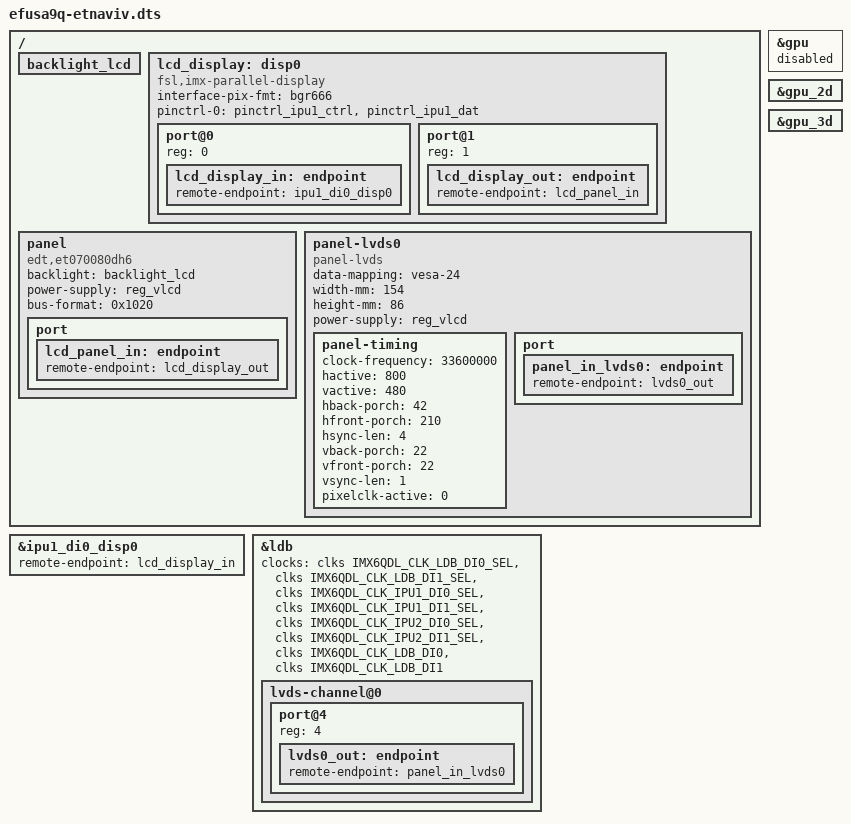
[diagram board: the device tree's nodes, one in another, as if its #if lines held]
#include "efusa9q.dts"

/ {
#ifdef CONFIG_EFUSA9_LCD
	backlight_lcd:backlight_lcd {
	};

	lcd_display: disp0 {
		compatible = "fsl,imx-parallel-display";
		#address-cells = <1>;
		#size-cells = <0>;
		interface-pix-fmt = "bgr666";

		pinctrl-names = "default";
		pinctrl-0 = <&pinctrl_ipu1_ctrl &pinctrl_ipu1_dat>;
		status = "okay";

		port@0 {
			reg = <0>;

			lcd_display_in: endpoint {
				remote-endpoint = <&ipu1_di0_disp0>;
			};
		};

		port@1 {
			reg = <1>;

			lcd_display_out: endpoint {
				remote-endpoint = <&lcd_panel_in>;
			};
		};
	};

	panel: panel {
		/*
		 * edt,et057090dhu: EDT 5.7" LCD TFT
		 * edt,et070080dh6: EDT 7.0" LCD TFT
		 */
		compatible = "edt,et070080dh6";
		backlight = <&backlight_lcd>;
		power-supply = <&reg_vlcd>;
		bus-format = <0x1020>; /*BGR*/
		port {
			lcd_panel_in: endpoint {
				remote-endpoint = <&lcd_display_out>;
			};
		};
	};
#endif

#ifdef CONFIG_EFUSA9_LVDS0
	panel-lvds0 {
		compatible = "panel-lvds";
		data-mapping = "vesa-24";
		width-mm = <154>;
		height-mm = <86>;
		power-supply = <&reg_vlcd>;
		panel-timing {
				clock-frequency = <33600000>;
				hactive = <800>;
				vactive = <480>;
				hback-porch = <42>;
				hfront-porch = <210>;
				hsync-len = <4>;
				vback-porch = <22>;
				vfront-porch = <22>;
				vsync-len = <1>;
				pixelclk-active = <0>;
		};
		port {
			panel_in_lvds0: endpoint {
				remote-endpoint = <&lvds0_out>;
			};
		};
	};
#endif
};

&gpu {
	status = "disabled";
};

&gpu_2d {
	status = "okay";
};

&gpu_3d {
	status = "okay";
};
#ifdef CONFIG_EFUSA9_LCD
&ipu1_di0_disp0 {
	remote-endpoint = <&lcd_display_in>;
};
#endif

#ifdef CONFIG_EFUSA9_LVDS0
&ldb {
	clocks = <&clks IMX6QDL_CLK_LDB_DI0_SEL>, <&clks IMX6QDL_CLK_LDB_DI1_SEL>,
		 <&clks IMX6QDL_CLK_IPU1_DI0_SEL>, <&clks IMX6QDL_CLK_IPU1_DI1_SEL>,
		 <&clks IMX6QDL_CLK_IPU2_DI0_SEL>, <&clks IMX6QDL_CLK_IPU2_DI1_SEL>,
		 <&clks IMX6QDL_CLK_LDB_DI0>, <&clks IMX6QDL_CLK_LDB_DI1>;
	clock-names = "di0_pll", "di1_pll",
		      "di0_sel", "di1_sel", "di2_sel", "di3_sel",
		      "di0", "di1";

	status = "okay";

	lvds-channel@0 {
		status = "okay";

		port@4 {
			reg = <4>;

			lvds0_out: endpoint {
				remote-endpoint = <&panel_in_lvds0>;
			};
		};
	};
};
#endif
